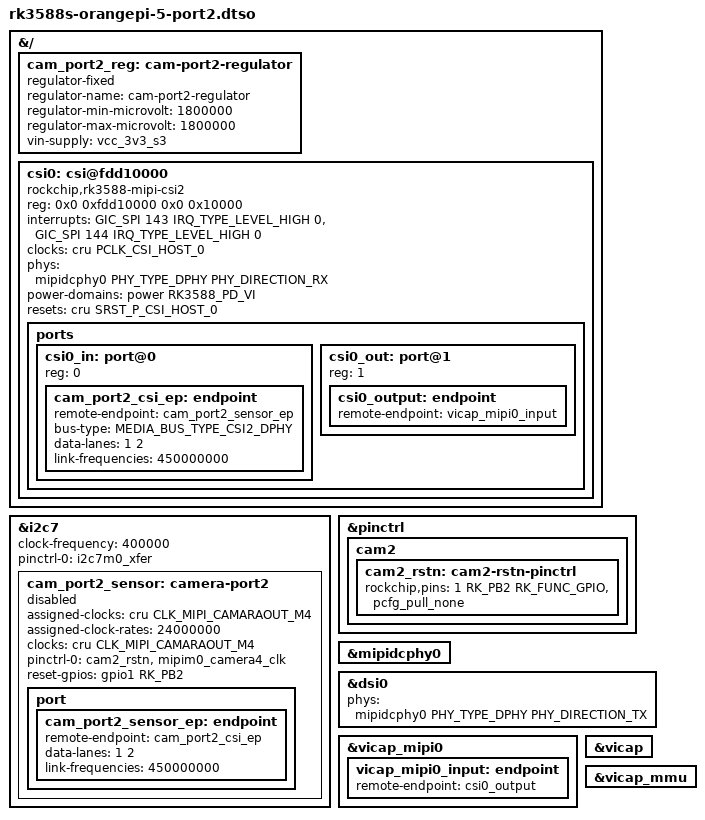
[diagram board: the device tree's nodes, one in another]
// SPDX-License-Identifier: (GPL-2.0+ OR MIT)
/*
 * Orange Pi 5 / 5B CAM2 (port2): Samsung DCPHY0 CSI RX + CSI0 on i2c7.
 *
 * Publishes cam_port2_sensor, cam_port2_sensor_ep, cam_port2_csi_ep,
 * and cam_port2_reg. Shares i2c7 with port1, so the sensor node is named
 * camera-port2.
 *
 * Also adds the csi0 host from kernel patch 0005, which stock DTBs lack,
 * and switches DCPHY0 to two phy-cells so that host can select the
 * receiver. That needs the DCPHY module from rk3588-camera-dkms: the stock
 * module has no receiver and rejects two cells.
 */

/dts-v1/;
/plugin/;

#include <dt-bindings/clock/rockchip,rk3588-cru.h>
#include <dt-bindings/gpio/gpio.h>
#include <dt-bindings/interrupt-controller/arm-gic.h>
#include <dt-bindings/media/video-interfaces.h>
#include <dt-bindings/phy/phy.h>
#include <dt-bindings/pinctrl/rockchip.h>
#include <dt-bindings/power/rk3588-power.h>
#include <dt-bindings/reset/rockchip,rk3588-cru.h>

&{/} {
	cam_port2_reg: cam-port2-regulator {
		compatible = "regulator-fixed";
		regulator-name = "cam-port2-regulator";
		regulator-min-microvolt = <1800000>;
		regulator-max-microvolt = <1800000>;
		vin-supply = <&vcc_3v3_s3>;
	};

	csi0: csi@fdd10000 {
		compatible = "rockchip,rk3588-mipi-csi2", "rockchip,rk3568-mipi-csi2";
		reg = <0x0 0xfdd10000 0x0 0x10000>;
		interrupts = <GIC_SPI 143 IRQ_TYPE_LEVEL_HIGH 0>,
			     <GIC_SPI 144 IRQ_TYPE_LEVEL_HIGH 0>;
		interrupt-names = "err1", "err2";
		clocks = <&cru PCLK_CSI_HOST_0>;
		phys = <&mipidcphy0 PHY_TYPE_DPHY PHY_DIRECTION_RX>;
		power-domains = <&power RK3588_PD_VI>;
		resets = <&cru SRST_P_CSI_HOST_0>;
		status = "okay";

		ports {
			#address-cells = <1>;
			#size-cells = <0>;

			csi0_in: port@0 {
				reg = <0>;

				cam_port2_csi_ep: endpoint {
					remote-endpoint = <&cam_port2_sensor_ep>;
					bus-type = <MEDIA_BUS_TYPE_CSI2_DPHY>;
					data-lanes = <1 2>;
					link-frequencies = /bits/ 64 <450000000>;
				};
			};

			csi0_out: port@1 {
				reg = <1>;

				csi0_output: endpoint {
					remote-endpoint = <&vicap_mipi0_input>;
				};
			};
		};
	};
};

&i2c7 {
	#address-cells = <1>;
	#size-cells = <0>;
	clock-frequency = <400000>;
	pinctrl-names = "default";
	pinctrl-0 = <&i2c7m0_xfer>;
	status = "okay";

	cam_port2_sensor: camera-port2 {
		status = "disabled";
		assigned-clocks = <&cru CLK_MIPI_CAMARAOUT_M4>;
		assigned-clock-rates = <24000000>;
		clocks = <&cru CLK_MIPI_CAMARAOUT_M4>;
		pinctrl-names = "default";
		pinctrl-0 = <&cam2_rstn &mipim0_camera4_clk>;
		reset-gpios = <&gpio1 RK_PB2 GPIO_ACTIVE_HIGH>;

		port {
			cam_port2_sensor_ep: endpoint {
				remote-endpoint = <&cam_port2_csi_ep>;
				data-lanes = <1 2>;
				link-frequencies = /bits/ 64 <450000000>;
			};
		};
	};
};

&pinctrl {
	cam2 {
		cam2_rstn: cam2-rstn-pinctrl {
			rockchip,pins = <1 RK_PB2 RK_FUNC_GPIO &pcfg_pull_none>;
		};
	};
};

/* Two cells: mode, then transmitter (DSI) or receiver (CSI). */
&mipidcphy0 {
	#phy-cells = <2>;
	status = "okay";
};

/* dsi0 is parsed with the PHY's #phy-cells even while disabled. */
&dsi0 {
	phys = <&mipidcphy0 PHY_TYPE_DPHY PHY_DIRECTION_TX>;
};

&vicap_mipi0 {
	vicap_mipi0_input: endpoint {
		remote-endpoint = <&csi0_output>;
	};
};

&vicap {
	status = "okay";
};

&vicap_mmu {
	status = "okay";
};
